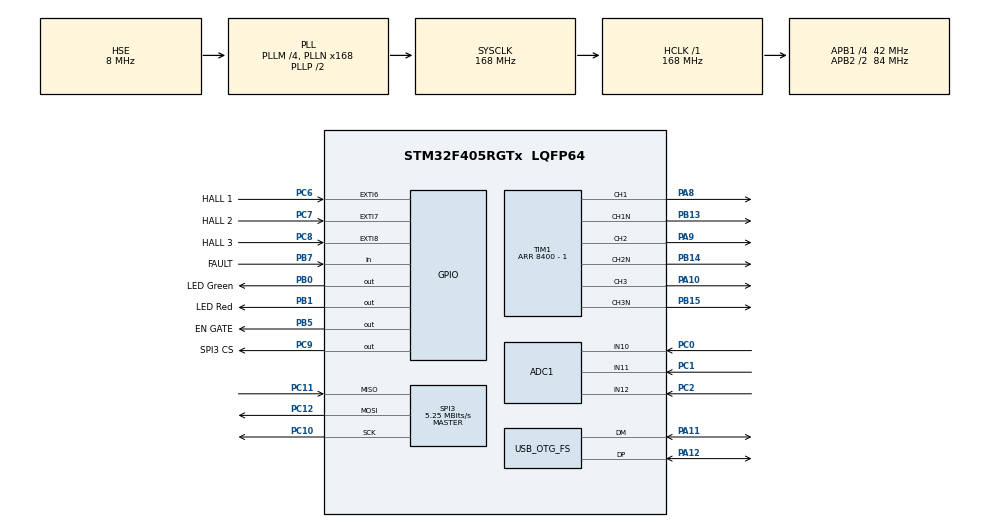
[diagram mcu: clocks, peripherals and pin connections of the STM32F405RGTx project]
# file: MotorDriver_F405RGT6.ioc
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ADC1.Channel-2\#ChannelRegularConversion=ADC_CHANNEL_10
ADC1.NbrOfConversionFlag=1
ADC1.Rank-2\#ChannelRegularConversion=1
ADC1.SamplingTime-2\#ChannelRegularConversion=ADC_SAMPLETIME_3CYCLES
ADC1.master=1
Dma.ADC1.0.Direction=DMA_PERIPH_TO_MEMORY
Dma.ADC1.0.FIFOMode=DMA_FIFOMODE_DISABLE
Dma.ADC1.0.Instance=DMA2_Stream0
Dma.ADC1.0.MemDataAlignment=DMA_MDATAALIGN_HALFWORD
Dma.ADC1.0.MemInc=DMA_MINC_ENABLE
Dma.ADC1.0.Mode=DMA_CIRCULAR
Dma.ADC1.0.PeriphDataAlignment=DMA_PDATAALIGN_HALFWORD
Dma.ADC1.0.PeriphInc=DMA_PINC_DISABLE
Dma.ADC1.0.Priority=DMA_PRIORITY_LOW
Dma.Request0=ADC1
Mcu.Family=STM32F4
Mcu.Name=STM32F405RGTx
Mcu.Package=LQFP64
NVIC.ADC_IRQn=true\:0\:0\:false\:false\:true\:true\:true\:true
NVIC.DMA2_Stream0_IRQn=true\:0\:0\:false\:false\:true\:false\:true\:true
NVIC.EXTI9_5_IRQn=true\:0\:0\:false\:false\:true\:true\:true\:true
NVIC.OTG_FS_IRQn=true\:0\:0\:false\:false\:true\:true\:true\:true
NVIC.PriorityGroup=NVIC_PRIORITYGROUP_4
NVIC.SPI3_IRQn=true\:0\:0\:false\:false\:true\:true\:true\:true
NVIC.TIM1_BRK_TIM9_IRQn=true\:0\:0\:false\:false\:true\:true\:true\:true
NVIC.TIM1_CC_IRQn=true\:0\:0\:false\:false\:true\:true\:true\:true
NVIC.TIM1_TRG_COM_TIM11_IRQn=true\:0\:0\:false\:false\:true\:true\:true\:true
NVIC.TIM1_UP_TIM10_IRQn=true\:0\:0\:false\:false\:true\:true\:true\:true
PA10.Signal=S_TIM1_CH3
PA11.Mode=Device_Only
PA11.Signal=USB_OTG_FS_DM
PA12.Mode=Device_Only
PA12.Signal=USB_OTG_FS_DP
PA13.Mode=Serial_Wire
PA13.Signal=SYS_JTMS-SWDIO
PA14.Mode=Serial_Wire
PA14.Signal=SYS_JTCK-SWCLK
PA8.Signal=S_TIM1_CH1
PA9.Signal=S_TIM1_CH2
PB0.GPIO_Label=LED Green
PB0.Signal=GPIO_Output
PB1.GPIO_Label=LED Red
PB1.Signal=GPIO_Output
PB13.Mode=PWM Generation1 CH1 CH1N
PB13.Signal=TIM1_CH1N
PB14.Mode=PWM Generation2 CH2 CH2N
PB14.Signal=TIM1_CH2N
PB15.Mode=PWM Generation3 CH3 CH3N
PB15.Signal=TIM1_CH3N
PB5.GPIO_Label=EN GATE
PB5.Signal=GPIO_Output
PB7.GPIO_Label=FAULT
PB7.GPIO_PuPd=GPIO_PULLUP
PB7.Signal=GPIO_Input
PC0.Signal=ADCx_IN10
PC1.Signal=ADCx_IN11
PC10.Mode=Full_Duplex_Master
PC10.Signal=SPI3_SCK
PC11.Mode=Full_Duplex_Master
PC11.Signal=SPI3_MISO
PC12.Mode=Full_Duplex_Master
PC12.Signal=SPI3_MOSI
PC14-OSC32_IN.Mode=LSE-External-Oscillator
PC14-OSC32_IN.Signal=RCC_OSC32_IN
PC15-OSC32_OUT.Mode=LSE-External-Oscillator
PC15-OSC32_OUT.Signal=RCC_OSC32_OUT
PC2.Signal=ADCx_IN12
PC6.GPIO_Label=HALL 1
PC6.GPIO_ModeDefaultEXTI=GPIO_MODE_IT_RISING_FALLING
PC6.GPIO_PuPd=GPIO_NOPULL
PC6.Signal=GPXTI6
PC7.GPIO_Label=HALL 2
PC7.GPIO_ModeDefaultEXTI=GPIO_MODE_IT_RISING_FALLING
PC7.Signal=GPXTI7
PC8.GPIO_Label=HALL 3
PC8.GPIO_ModeDefaultEXTI=GPIO_MODE_IT_RISING_FALLING
PC8.Signal=GPXTI8
PC9.GPIO_Label=SPI3 CS
PC9.Signal=GPIO_Output
PH0-OSC_IN.Mode=HSE-External-Oscillator
PH0-OSC_IN.Signal=RCC_OSC_IN
PH1-OSC_OUT.Mode=HSE-External-Oscillator
PH1-OSC_OUT.Signal=RCC_OSC_OUT
ProjectManager.HeapSize=0x200
ProjectManager.StackSize=0x400
ProjectManager.TargetToolchain=MDK-ARM V5.32
RCC.48MHZClocksFreq_Value=48000000
RCC.AHBFreq_Value=168000000
RCC.APB1CLKDivider=RCC_HCLK_DIV4
RCC.APB1Freq_Value=42000000
RCC.APB1TimFreq_Value=84000000
RCC.APB2CLKDivider=RCC_HCLK_DIV2
RCC.APB2Freq_Value=84000000
RCC.APB2TimFreq_Value=168000000
RCC.CortexFreq_Value=168000000
RCC.HCLKFreq_Value=168000000
RCC.HSE_VALUE=8000000
RCC.HSI_VALUE=16000000
RCC.PLLM=4
RCC.PLLN=168
RCC.PLLQ=7
RCC.SYSCLKFreq_VALUE=168000000
RCC.SYSCLKSource=RCC_SYSCLKSOURCE_PLLCLK
RCC.VCOOutputFreq_Value=336000000
SH.ADCx_IN10.0=ADC1_IN10,IN10
SH.ADCx_IN11.0=ADC1_IN11,IN11
SH.ADCx_IN12.0=ADC1_IN12,IN12
SH.S_TIM1_CH1.0=TIM1_CH1,PWM Generation1 CH1 CH1N
SH.S_TIM1_CH2.0=TIM1_CH2,PWM Generation2 CH2 CH2N
SH.S_TIM1_CH3.0=TIM1_CH3,PWM Generation3 CH3 CH3N
SPI3.BaudRatePrescaler=SPI_BAUDRATEPRESCALER_8
SPI3.CLKPhase=SPI_PHASE_2EDGE
SPI3.CalculateBaudRate=5.25 MBits/s
SPI3.DataSize=SPI_DATASIZE_16BIT
SPI3.Direction=SPI_DIRECTION_2LINES
SPI3.Mode=SPI_MODE_MASTER
SPI3.VirtualType=VM_MASTER
TIM1.AutoReloadPreload=TIM_AUTORELOAD_PRELOAD_ENABLE
TIM1.Channel-PWM\ Generation1\ CH1\ CH1N=TIM_CHANNEL_1
TIM1.Channel-PWM\ Generation2\ CH2\ CH2N=TIM_CHANNEL_2
TIM1.Channel-PWM\ Generation3\ CH3\ CH3N=TIM_CHANNEL_3
TIM1.CounterMode=TIM_COUNTERMODE_UP
TIM1.Period=8400 - 1
USB_DEVICE.CLASS_NAME_FS=CDC
USB_DEVICE.VirtualMode-CDC_FS=Cdc
USB_DEVICE.VirtualModeFS=Cdc_FS
USB_OTG_FS.VirtualMode=Device_Only
VP_TIM1_VS_ClockSourceINT.Mode=Internal
VP_USB_DEVICE_VS_USB_DEVICE_CDC_FS.Mode=CDC_FS
board=custom

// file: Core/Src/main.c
/* USER CODE BEGIN Header */
/**
  ******************************************************************************
  * @file           : main.c
  * @brief          : Main program body
  ******************************************************************************
  * @attention
  *
  * Copyright (c) 2026 STMicroelectronics.
  * All rights reserved.
  *
  * This software is licensed under terms that can be found in the LICENSE file
  * in the root directory of this software component.
  * If no LICENSE file comes with this software, it is provided AS-IS.
  *
  ******************************************************************************
  */
/* USER CODE END Header */
#include "main.h"
#include "adc.h"
#include "dma.h"
#include "spi.h"
#include "tim.h"
#include "usb_device.h"
#include "gpio.h"

/* USER CODE BEGIN Includes */
#include "bldc.h"
#include "usbd_cdc_if.h"
#include <stdio.h>
/* USER CODE END Includes */

/* USER CODE BEGIN PV */
uint8_t g_sum_hall_state;
/* USER CODE END PV */

void SystemClock_Config(void);

int main(void)
{

  /* MCU Configuration--------------------------------------------------------*/

  /* Reset of all peripherals, Initializes the Flash interface and the Systick. */
  HAL_Init();

  /* Configure the system clock */
  SystemClock_Config();

  /* Initialize all configured peripherals */
  MX_GPIO_Init();
  MX_DMA_Init();
  MX_SPI3_Init();
  MX_TIM1_Init();
  MX_USB_DEVICE_Init();
  MX_ADC1_Init();
  /* USER CODE BEGIN 2 */
  motor_init();
  /* USER CODE END 2 */

  /* Infinite loop */
  /* USER CODE BEGIN WHILE */
  while (1)
  {
        char vofa_buf[32];
        int vofa_len;

        vofa_len = snprintf(vofa_buf, sizeof(vofa_buf), "%.3lf, %.3lf, %.3lf\n",
			(double)htim1.Instance -> CCR1, (double)htim1.Instance -> CCR2, (double)htim1.Instance -> CCR3);

        if (vofa_len > 0)
        {
          CDC_Transmit_FS((uint8_t *)vofa_buf, (uint16_t)vofa_len);
        }

    /* USER CODE END WHILE */

  }
}

void SystemClock_Config(void)
{
  RCC_OscInitTypeDef RCC_OscInitStruct = {0};
  RCC_ClkInitTypeDef RCC_ClkInitStruct = {0};

  /** Configure the main internal regulator output voltage
  */
  __HAL_RCC_PWR_CLK_ENABLE();
  __HAL_PWR_VOLTAGESCALING_CONFIG(PWR_REGULATOR_VOLTAGE_SCALE1);

  /** Initializes the RCC Oscillators according to the specified parameters
  * in the RCC_OscInitTypeDef structure.
  */
  RCC_OscInitStruct.OscillatorType = RCC_OSCILLATORTYPE_HSE;
  RCC_OscInitStruct.HSEState = RCC_HSE_ON;
  RCC_OscInitStruct.PLL.PLLState = RCC_PLL_ON;
  RCC_OscInitStruct.PLL.PLLSource = RCC_PLLSOURCE_HSE;
  RCC_OscInitStruct.PLL.PLLM = 4;
  RCC_OscInitStruct.PLL.PLLN = 168;
  RCC_OscInitStruct.PLL.PLLP = RCC_PLLP_DIV2;
  RCC_OscInitStruct.PLL.PLLQ = 7;
  if (HAL_RCC_OscConfig(&RCC_OscInitStruct) != HAL_OK)
  {
    Error_Handler();
  }

  /** Initializes the CPU, AHB and APB buses clocks
  */
  RCC_ClkInitStruct.ClockType = RCC_CLOCKTYPE_HCLK|RCC_CLOCKTYPE_SYSCLK
                              |RCC_CLOCKTYPE_PCLK1|RCC_CLOCKTYPE_PCLK2;
  RCC_ClkInitStruct.SYSCLKSource = RCC_SYSCLKSOURCE_PLLCLK;
  RCC_ClkInitStruct.AHBCLKDivider = RCC_SYSCLK_DIV1;
  RCC_ClkInitStruct.APB1CLKDivider = RCC_HCLK_DIV4;
  RCC_ClkInitStruct.APB2CLKDivider = RCC_HCLK_DIV2;

  if (HAL_RCC_ClockConfig(&RCC_ClkInitStruct, FLASH_LATENCY_5) != HAL_OK)
  {
    Error_Handler();
  }
}

void Error_Handler(void)
{
  __disable_irq();
  while (1)
  {
  }
}
